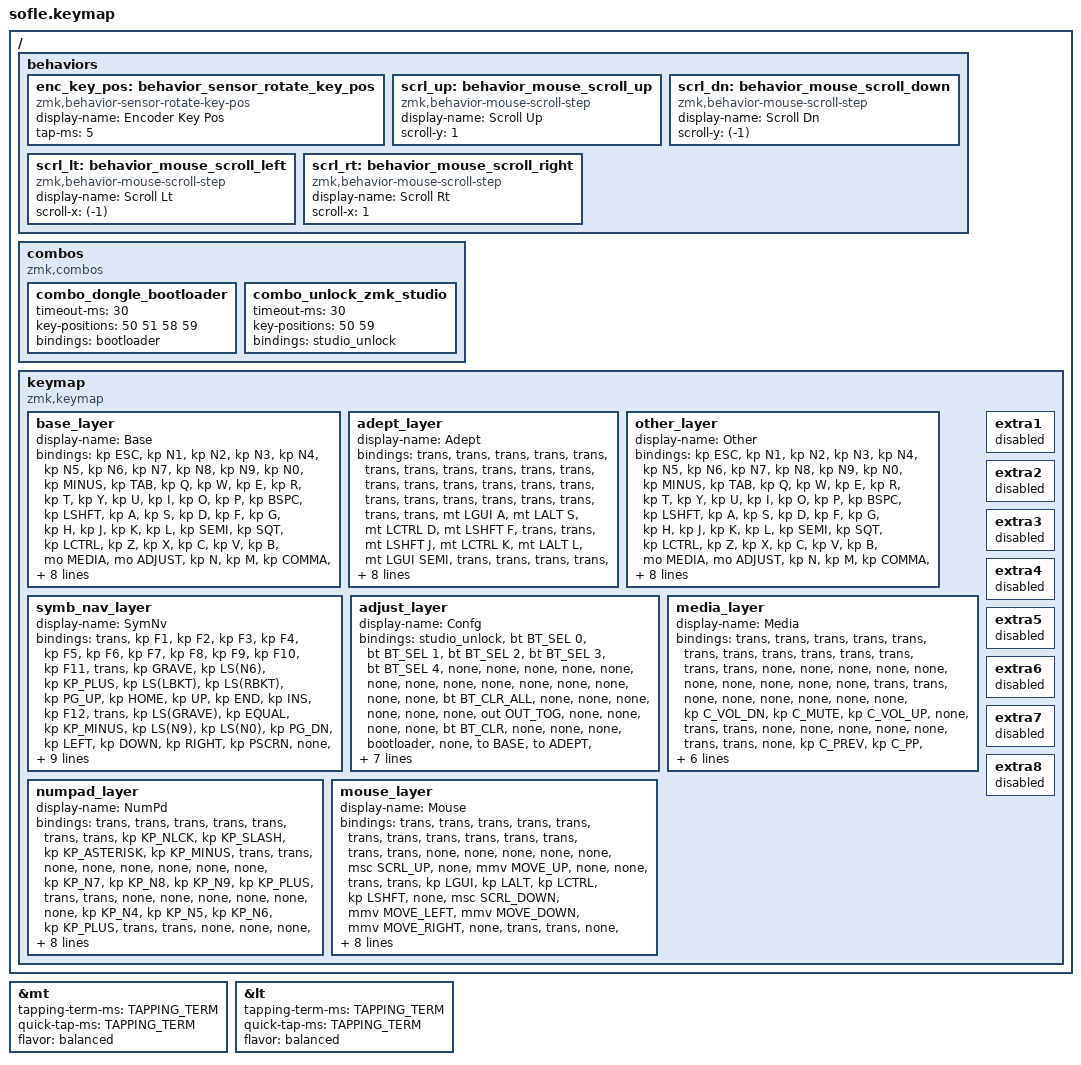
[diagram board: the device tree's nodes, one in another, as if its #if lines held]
/*
 * Copyright (c) 2020 The ZMK Contributors
 *
 * SPDX-License-Identifier: MIT
 */

#include <behaviors.dtsi>
#include <dt-bindings/zmk/keys.h>
#include <dt-bindings/zmk/bt.h>
#include <dt-bindings/zmk/rgb.h>
#include <dt-bindings/zmk/ext_power.h>
#include <dt-bindings/zmk/pointing.h>
#include <dt-bindings/zmk/outputs.h>

// Enumera as camadas do teclado
#define BASE 0
#define ADEPT 1
#define OTHER 2
#define SYMB_NAV 3
#define ADJUST 4
#define MEDIA 5
#define NUMPAD 6
#define MOUSE 7

// Posicoes virtuais para rotacao dos knobs no ZMK Studio (indices 60..63)
#define KNOB_L_CW  60
#define KNOB_L_CCW 61
#define KNOB_R_CW  62
#define KNOB_R_CCW 63

// ABNT2 keycodes
// Mapeamento de teclas ABNT2 que são usados para o layout brasileiro
// Inspired by https://github.com/qmk/qmk_firmware/blob/master/quantum/keymap_extras/keymap_brazilian_abnt2.h
#define BR_SLSH INT1
#define BR_ACUT LBKT
#define BR_RBKT NUHS
#define BR_RBCT LS(NUHS)
#define BR_LBKT RBKT
#define BR_LBCT LS(RBKT)

// Abaixo, há especificações do comportamento do tap-hold para teclas com duplo comportamento
// Para mais detalhes: https://zmk.dev/docs/keymaps/behaviors/hold-tap

#define TAPPING_TERM 300 // Tempo em milissegundos para diferenciar o tap-hold

// Para teclas com tap-hold em que o hold é um modificador, como CTRL, ALT, etc
&mt {
    tapping-term-ms = <TAPPING_TERM>;
    quick-tap-ms = <TAPPING_TERM>;
    flavor = "balanced"; // Pode ser "balanced", "hold-preferred" ou "tap-preferred"
};

// Para teclas com tap-hold em que o hold é uma mudança de camada, como SYMB_NAV, MEDIA, etc
&lt {
    tapping-term-ms = <TAPPING_TERM>;
    quick-tap-ms = <TAPPING_TERM>;
    flavor = "balanced"; // Pode ser "balanced", "hold-preferred" ou "tap-preferred"
};


// Behavior customizado que redireciona o giro dos knobs para posicoes virtuais do keymap
// e behaviors de scroll de mouse por passo (compativeis com ZMK Studio e knobs)
/ {
    behaviors {
        enc_key_pos: behavior_sensor_rotate_key_pos {
            compatible = "zmk,behavior-sensor-rotate-key-pos";
            #sensor-binding-cells = <2>;
            display-name = "Encoder Key Pos";
            tap-ms = <5>;
        };

        scrl_up: behavior_mouse_scroll_up {
            compatible = "zmk,behavior-mouse-scroll-step";
            #binding-cells = <0>;
            display-name = "Scroll Up";
            scroll-y = <1>;
        };

        scrl_dn: behavior_mouse_scroll_down {
            compatible = "zmk,behavior-mouse-scroll-step";
            #binding-cells = <0>;
            display-name = "Scroll Dn";
            scroll-y = <(-1)>;
        };

        scrl_lt: behavior_mouse_scroll_left {
            compatible = "zmk,behavior-mouse-scroll-step";
            #binding-cells = <0>;
            display-name = "Scroll Lt";
            scroll-x = <(-1)>;
        };

        scrl_rt: behavior_mouse_scroll_right {
            compatible = "zmk,behavior-mouse-scroll-step";
            #binding-cells = <0>;
            display-name = "Scroll Rt";
            scroll-x = <1>;
        };
    };
};

// Combos do teclado
/ {
    combos {
        compatible = "zmk,combos";
        combo_dongle_bootloader {
            // Faz o dongle entrar em modo de bootloader, para gravacao do firmware
            timeout-ms = <30>; // Tempo de tolerancia para apertar as teclas ao mesmo tempo
            key-positions = <50 51 58 59>; // 2 primeiras e 2 ultimas teclas da linha de teclas mais abaixo do teclado
            bindings = <&bootloader>; // Tecla a ser simulada ao apertar a combinação acima
        };
        combo_unlock_zmk_studio {
            // Desbloqueia o ZMK Studio
            timeout-ms = <30>; // Tempo de tolerancia para apertar as teclas ao mesmo tempo
            key-positions = <50 59>; // primeira e última teclas da linha de teclas mais abaixo do teclado
            bindings = <&studio_unlock>; // Tecla a ser simulada ao apertar a combinação acima
        };
    };
};


// Mapeamento de teclas e camadas do teclado
/ {
    keymap {
        compatible = "zmk,keymap";

// Uma cópia genérica do template de camada, que pode ser usada para criar novas camadas
//        name_layer {
//            display-name = "name";
//            bindings = <
//&trans    &trans    &trans    &trans      &trans    &trans                        &trans    &trans   &trans    &trans    &trans   &trans
//&trans    &none     &none     &none       &none     &none                         &none     &none    &none     &none     &none    &trans
//&trans    &none     &none     &none       &none     &none                         &none     &none    &none     &none     &none    &trans
//&trans    &none     &none     &none       &none     &none      &trans    &trans   &none     &none    &none     &none     &none    &trans
//                    &trans    &trans      &trans    &trans     &trans    &trans   &trans    &trans   &trans    &trans
//                    &trans    &trans      &trans    &trans
//            >;
//
//            sensor-bindings = <&enc_key_pos KNOB_L_CW KNOB_L_CCW &enc_key_pos KNOB_R_CW KNOB_R_CCW>; // Para o knob (encoder)
//        };

        base_layer {
            display-name = "Base";
            bindings = <
#ifdef USE_INTERNATIONAL_LAYOUT
&kp ESC   &kp N1 &kp N2     &kp N3   &kp N4    &kp N5                               &kp N6 &kp N7     &kp N8    &kp N9   &kp N0    &kp MINUS
&kp TAB   &kp Q  &kp W      &kp E    &kp R     &kp T                                &kp Y  &kp U      &kp I     &kp O    &kp P     &kp BSPC
&kp LSHFT &kp A  &kp S      &kp D    &kp F     &kp G                                &kp H  &kp J      &kp K     &kp L    &kp SEMI  &kp SQT
&kp LCTRL &kp Z  &kp X      &kp C    &kp V     &kp B     &mo MEDIA       &mo ADJUST &kp N  &kp M      &kp COMMA &kp DOT  &kp FSLH  &kp ENTER
                 &mo NUMPAD &kp LGUI &kp LALT &kp SPACE  &mo SYMB_NAV    &kp ENTER  &kp BSPC  &kp DEL &kp RGUI  &kp RCTRL
#else
&kp ESC   &kp N1 &kp N2     &kp N3   &kp N4    &kp N5                               &kp N6 &kp N7     &kp N8    &kp N9   &kp N0    &kp BSPC
&kp TAB   &kp Q  &kp W      &kp E    &kp R     &kp T                                &kp Y  &kp U      &kp I     &kp O    &kp P     &kp BR_ACUT
&kp LSHFT &kp A  &kp S      &kp D    &kp F     &kp G                                &kp H  &kp J      &kp K     &kp L    &kp SEMI  &kp SQT
&kp LCTRL &kp Z  &kp X      &kp C    &kp V     &kp B     &mo MEDIA       &mo ADJUST &kp N  &kp M      &kp COMMA &kp DOT  &kp FSLH  &kp BR_SLSH
                 &mo NUMPAD &kp LGUI &kp LALT &kp SPACE  &mo SYMB_NAV    &kp ENTER  &kp BSPC  &kp DEL &kp RGUI  &kp RCTRL
#endif
                 // Rotacao dos knobs: Esq Horario (60), Esq Anti-horario (61), Dir Horario (62), Dir Anti-horario (63)
                 &kp C_VOL_UP &kp C_VOL_DN &kp PG_UP &kp PG_DN
            >;
            sensor-bindings = <&enc_key_pos KNOB_L_CW KNOB_L_CCW &enc_key_pos KNOB_R_CW KNOB_R_CCW>;
        };

        adept_layer {
            display-name = "Adept";
            bindings = <
&trans    &trans     &trans     &trans      &trans      &trans                                      &trans    &trans      &trans      &trans     &trans        &trans
&trans    &trans     &trans     &trans      &trans      &trans                                      &trans    &trans      &trans      &trans     &trans        &trans
&trans    &mt LGUI A &mt LALT S &mt LCTRL D &mt LSHFT F &trans                                      &trans    &mt LSHFT J &mt LCTRL K &mt LALT L &mt LGUI SEMI &trans
&trans    &trans     &trans     &trans      &trans      &trans           &trans             &trans  &trans    &trans      &trans      &trans     &trans        &trans
                     &trans     &trans      &trans      &lt MOUSE SPACE  &lt SYMB_NAV TAB   &trans  &trans    &trans      &trans      &trans
                     &trans     &trans      &trans      &trans
            >;

            sensor-bindings = <&enc_key_pos KNOB_L_CW KNOB_L_CCW &enc_key_pos KNOB_R_CW KNOB_R_CCW>;
        };

        // By defaults its equal to base_layer. To be customized by user.
        other_layer {
            display-name = "Other";
            bindings = <
#ifdef USE_INTERNATIONAL_LAYOUT
&kp ESC   &kp N1 &kp N2     &kp N3   &kp N4    &kp N5                               &kp N6 &kp N7     &kp N8    &kp N9   &kp N0    &kp MINUS
&kp TAB   &kp Q  &kp W      &kp E    &kp R     &kp T                                &kp Y  &kp U      &kp I     &kp O    &kp P     &kp BSPC
&kp LSHFT &kp A  &kp S      &kp D    &kp F     &kp G                                &kp H  &kp J      &kp K     &kp L    &kp SEMI  &kp SQT
&kp LCTRL &kp Z  &kp X      &kp C    &kp V     &kp B     &mo MEDIA       &mo ADJUST &kp N  &kp M      &kp COMMA &kp DOT  &kp FSLH  &kp ENTER
                 &mo NUMPAD &kp LGUI &kp LALT &kp SPACE  &mo SYMB_NAV    &kp ENTER  &kp BSPC  &kp DEL &kp RGUI  &kp RCTRL
#else
&kp ESC   &kp N1 &kp N2     &kp N3   &kp N4    &kp N5                               &kp N6 &kp N7     &kp N8    &kp N9   &kp N0    &kp BSPC
&kp TAB   &kp Q  &kp W      &kp E    &kp R     &kp T                                &kp Y  &kp U      &kp I     &kp O    &kp P     &kp BR_ACUT
&kp LSHFT &kp A  &kp S      &kp D    &kp F     &kp G                                &kp H  &kp J      &kp K     &kp L    &kp SEMI  &kp SQT
&kp LCTRL &kp Z  &kp X      &kp C    &kp V     &kp B     &mo MEDIA       &mo ADJUST &kp N  &kp M      &kp COMMA &kp DOT  &kp FSLH  &kp BR_SLSH
                 &mo NUMPAD &kp LGUI &kp LALT &kp SPACE  &mo SYMB_NAV    &kp ENTER  &kp BSPC  &kp DEL &kp RGUI  &kp RCTRL
#endif
                 &kp C_VOL_UP &kp C_VOL_DN &kp PG_UP &kp PG_DN
            >;

            sensor-bindings = <&enc_key_pos KNOB_L_CW KNOB_L_CCW &enc_key_pos KNOB_R_CW KNOB_R_CCW>;
        };

        symb_nav_layer {
            display-name = "SymNv";
            bindings = <
#ifdef USE_INTERNATIONAL_LAYOUT
&trans    &kp F1        &kp F2       &kp F3        &kp F4       &kp F5                        &kp F6    &kp F7       &kp F8    &kp F9        &kp F10           &kp F11
&trans    &kp GRAVE     &kp LS(N6)   &kp KP_PLUS   &kp LS(LBKT) &kp LS(RBKT)                  &kp PG_UP &kp HOME     &kp UP    &kp END       &kp INS           &kp F12
&trans    &kp LS(GRAVE) &kp EQUAL    &kp KP_MINUS  &kp LS(N9)   &kp LS(N0)                    &kp PG_DN &kp LEFT     &kp DOWN  &kp RIGHT     &kp PSCRN         &none
&trans    &kp NUBS      &kp LS(NUBS) &kp LS(MINUS) &kp LBKT     &kp RBKT   &trans    &trans   &kp CAPS  &kp LC(LEFT) &kp ESC   &kp LC(RIGHT) &kp PAUSE_BREAK   &none
                        &trans       &trans        &trans       &trans     &trans    &trans   &trans    &trans       &trans    &trans
#else
&trans    &kp F1        &kp F2       &kp F3        &kp F4       &kp F5                        &kp F6    &kp F7       &kp F8    &kp F9        &kp F10           &kp F11
&trans    &kp GRAVE     &kp LS(N6)   &kp KP_PLUS   &kp BR_LBKT  &kp BR_RBKT                   &kp PG_UP &kp HOME     &kp UP    &kp END       &kp INS           &kp F12
&trans    &kp LS(GRAVE) &kp EQUAL    &kp KP_MINUS  &kp LS(N9)   &kp LS(N0)                    &kp PG_DN &kp LEFT     &kp DOWN  &kp RIGHT     &kp PSCRN         &none
&trans    &kp NUBS      &kp LS(NUBS) &kp LS(MINUS) &kp BR_LBCT  &kp BR_RBCT  &trans   &trans  &kp CAPS  &kp LC(LEFT) &kp ESC   &kp LC(RIGHT) &kp PAUSE_BREAK   &none
                        &trans       &trans        &trans       &trans       &trans   &trans  &trans    &trans       &trans    &trans
#endif
                        &trans       &trans        &trans       &trans
            >;

            sensor-bindings = <&enc_key_pos KNOB_L_CW KNOB_L_CCW &enc_key_pos KNOB_R_CW KNOB_R_CCW>;
        };

        adjust_layer {
            display-name = "Confg";
            bindings = <
&studio_unlock &bt BT_SEL 0 &bt BT_SEL 1 &bt BT_SEL 2 &bt BT_SEL 3 &bt BT_SEL 4                 &none    &none   &none          &none   &none   &none
&none          &none        &none        &none        &none        &none                        &none    &none   &bt BT_CLR_ALL &none   &none   &none
&none          &none        &none        &out OUT_TOG &none        &none                        &none    &none   &bt BT_CLR     &none   &none   &none
&bootloader    &none        &to BASE     &to ADEPT    &to OTHER    &none     &trans    &trans   &none    &none   &none          &none   &none   &bootloader
               &trans       &trans       &trans       &trans       &trans    &trans    &trans   &trans   &trans  &trans
               &trans       &trans       &trans       &trans
            >;

            sensor-bindings = <&enc_key_pos KNOB_L_CW KNOB_L_CCW &enc_key_pos KNOB_R_CW KNOB_R_CCW>;
        };

        media_layer {
            display-name = "Media";
            bindings = <
&trans    &trans    &trans    &trans      &trans    &trans                        &trans    &trans       &trans     &trans       &trans  &trans
&trans    &none     &none     &none       &none     &none                         &none     &none        &none      &none        &none   &trans
&trans    &none     &none     &none       &none     &none                         &none     &kp C_VOL_DN &kp C_MUTE &kp C_VOL_UP &none   &trans
&trans    &none     &none     &none       &none     &none      &trans    &trans   &none     &kp C_PREV   &kp C_PP   &kp C_NEXT   &none   &trans
                    &trans    &trans      &trans    &trans     &trans    &trans   &trans    &trans       &trans     &trans
                    &trans    &trans      &trans    &trans
            >;

            sensor-bindings = <&enc_key_pos KNOB_L_CW KNOB_L_CCW &enc_key_pos KNOB_R_CW KNOB_R_CCW>;
        };

        numpad_layer {
            display-name = "NumPd";
            bindings = <
&trans    &trans    &trans    &trans      &trans    &trans                        &trans    &kp KP_NLCK &kp KP_SLASH  &kp KP_ASTERISK  &kp KP_MINUS   &trans
&trans    &none     &none     &none       &none     &none                         &none     &kp KP_N7   &kp KP_N8     &kp KP_N9        &kp KP_PLUS    &trans
&trans    &none     &none     &none       &none     &none                         &none     &kp KP_N4   &kp KP_N5     &kp KP_N6        &kp KP_PLUS    &trans
&trans    &none     &none     &none       &none     &none      &trans    &trans   &none     &kp KP_N1   &kp KP_N2     &kp KP_N3        &kp KP_ENTER   &trans
                    &trans    &trans      &trans    &trans     &trans    &trans   &trans    &kp KP_N0   &kp KP_N0     &kp KP_DOT
                    &trans    &trans      &trans    &trans
            >;

            sensor-bindings = <&enc_key_pos KNOB_L_CW KNOB_L_CCW &enc_key_pos KNOB_R_CW KNOB_R_CCW>;
        };

        mouse_layer {
            display-name = "Mouse";
            bindings = <
&trans    &trans    &trans    &trans      &trans     &trans                          &trans         &trans         &trans         &trans          &trans    &trans
&trans    &none     &none     &none       &none      &none                           &msc SCRL_UP   &none          &mmv MOVE_UP   &none           &none     &trans
&trans    &kp LGUI  &kp LALT  &kp LCTRL   &kp LSHFT  &none                           &msc SCRL_DOWN &mmv MOVE_LEFT &mmv MOVE_DOWN &mmv MOVE_RIGHT &none     &trans
&trans    &none     &none     &none       &none      &none     &trans    &trans      &none          &none          &none          &none           &none     &trans
                    &trans    &trans      &trans     &trans    &trans    &mkp RCLK   &mkp LCLK      &mkp MCLK      &trans         &trans
                    &trans    &trans      &trans     &trans
            >;

            sensor-bindings = <&enc_key_pos KNOB_L_CW KNOB_L_CCW &enc_key_pos KNOB_R_CW KNOB_R_CCW>;
        };

        // Extra layers, so it can be added and customized in ZMK Studio
        extra1 {
            status = "reserved";
        };
        extra2 {
            status = "reserved";
        };
        extra3 {
            status = "reserved";
        };
        extra4 {
            status = "reserved";
        };
        extra5 {
            status = "reserved";
        };
        extra6 {
            status = "reserved";
        };
        extra7 {
            status = "reserved";
        };
        extra8 {
            status = "reserved";
        };
    };

};
